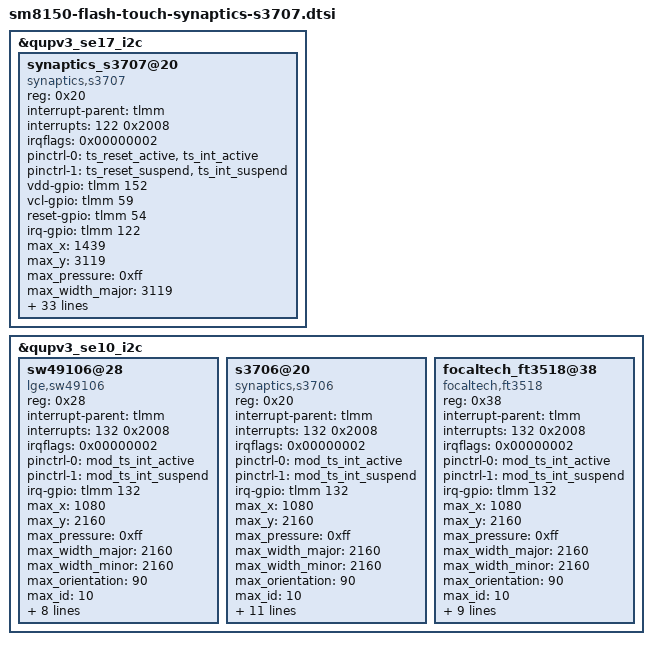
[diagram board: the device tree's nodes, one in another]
/* Copyright (c) 2014, The Linux Foundation. All rights reserved.
 *
 * This program is free software; you can redistribute it and/or modify
 * it under the terms of the GNU General Public License version 2 and
 * only version 2 as published by the Free Software Foundation.
 *
 * This program is distributed in the hope that it will be useful,
 * but WITHOUT ANY WARRANTY; without even the implied warranty of
 * MERCHANTABILITY or FITNESS FOR A PARTICULAR PURPOSE.  See the
 * GNU General Public License for more details.
 */


&qupv3_se17_i2c {
	status = "okay";

	synaptics_s3707@20 {
		status = "ok";
		compatible = "synaptics,s3707";

		reg = <0x20>;
		interrupt-parent = <&tlmm>;
		interrupts = <122 0x2008>;
		irqflags = <0x00000002>;

		pinctrl-names = "touch_pin_active", "touch_pin_sleep";
		pinctrl-0 = <&ts_reset_active &ts_int_active>;
		pinctrl-1 = <&ts_reset_suspend &ts_int_suspend>;

		vdd-gpio = <&tlmm 152 0x00>;
		vcl-gpio = <&tlmm 59 0x00>;
		reset-gpio = <&tlmm 54 0x00>;
		irq-gpio = <&tlmm 122 0x2008>;

		/* Caps */
		max_x = <1439>;
		max_y = <3119>;
		max_pressure = <0xff>;
		max_width_major = <3119>;
		max_width_minor = <3119>;
		max_orientation = <90>;
		max_id = <10>;
		hw_reset_delay = <100>;
		sw_reset_delay = <100>;

		/* Role */
		use_lpwg = <1>;
		use_lpwg_test = <1>;
		hide_coordinate = <1>;
		use_film_status = <1>;

		/* Firmware */
		fw_image = "touch/flash/main/lgd/PLG661-V1.08-PR2926255-s3707b_BLV86_DS5.10.81.1_50064188.img",
				"touch/flash/mfts/tianma/PLG670-V0.06-PR2910189-s3706b_BLV86_DS5.10.81.2_60062106.img",
				"touch/flash/mfts/tovis/PLG676-V0.06-PR2992791-s3707b_BLV86_DS5.10.81.2_20062106.img";
		panel_spec = "touch/flash/main/lgd/flash_limit.txt",
					"touch/flash/mfts/tianma/flash_tianma_limit.txt",
					"touch/flash/mfts/tovis/flash_tovis_limit.txt";
		panel_spec_mfts_folder = "touch/flash/main/lgd/flash_limit_mfts.txt",
					"touch/flash/mfts/tianma/flash_tianma_limit_mfts.txt",
					"touch/flash/mfts/tovis/flash_tovis_limit_mfts.txt";

		/* Performance Test */
		use_perf_test = <1>;
		test_delay = <8>;
		test_pressure = <50>;
		test_width = <100>;
		click_test_x = <180>;
		click_test_y = <756>;
		v_drag_test_x = <144>;
		v_drag_test_start_y = <1971>;
		v_drag_test_end_y = <1148>;
		h_drag_test_start_x = <1131>;
		h_drag_test_end_x = <308>;
		h_drag_test_y = <2184>;
	};
};

&qupv3_se10_i2c {
	status = "okay";

	sw49106@28 {
		compatible = "lge,sw49106";
		status = "ok";

		reg = <0x28>;
		interrupt-parent = <&tlmm>;
		interrupts = <132 0x2008>;
		irqflags = <0x00000002>;

		pinctrl-names = "module_touch_active","module_touch_sleep";	/*Touch GPIO pin name setting*/
		pinctrl-0 = <&mod_ts_int_active>;	/*Touch GPIO pin active setting*/
		pinctrl-1 = <&mod_ts_int_suspend>;	/*Touch GPIO pin suspend setting*/

//		vdd-gpio = <&tlmm 152 0x00>;
//		vcl-gpio = <&tlmm 59 0x00>;
//		reset-gpio = <&tlmm 54 0x00>;
		irq-gpio = <&tlmm 132 0x2008>;

		/* Caps */
		max_x = <1080>;
		max_y = <2160>;
		max_pressure = <0xff>;
		max_width_major = <2160>;
		max_width_minor = <2160>;
		max_orientation = <90>;
		max_id = <10>;
		hw_reset_delay = <210>;
		sw_reset_delay = <90>;

		fw_image = "touch/flash/module/temp/L0W55CV5_1_06.img";
		panel_spec = "touch/flash/module/temp/flash_limit.txt";
		panel_spec_mfts_folder = "touch/flash/module/temp/flash_limit_mfts.txt";
	};

	s3706@20 {
		compatible = "synaptics,s3706";
		status = "ok";

		reg = <0x20>;
		interrupt-parent = <&tlmm>;
		interrupts = <132 0x2008>;
		irqflags = <0x00000002>;

		pinctrl-names = "module_touch_active","module_touch_sleep";	/*Touch GPIO pin name setting*/
		pinctrl-0 = <&mod_ts_int_active>;	/*Touch GPIO pin active setting*/
		pinctrl-1 = <&mod_ts_int_suspend>;	/*Touch GPIO pin suspend setting*/

//		vdd-gpio = <&tlmm 152 0x00>;
//		vcl-gpio = <&tlmm 59 0x00>;
//		reset-gpio = <&tlmm 54 0x00>;
		irq-gpio = <&tlmm 132 0x2008>;

		/* Caps */
		max_x = <1080>;
		max_y = <2160>;
		max_pressure = <0xff>;
		max_width_major = <2160>;
		max_width_minor = <2160>;
		max_orientation = <90>;
		max_id = <10>;
		hw_reset_delay = <100>;
		sw_reset_delay = <100>;

		fw_image = "touch/flash/module/tianma/PLG670-V0.06-PR2910189-s3706b_BLV86_DS5.10.81.2_60062106.img",
				"touch/flash/module/tovis/PLG676-V0.06-PR2992791-s3707b_BLV86_DS5.10.81.2_20062106.img";
		panel_spec = "touch/flash/module/tianma/flash_module_tianma_limit.txt",
				"touch/flash/module/tovis/flash_module_tovis_limit.txt";
		panel_spec_mfts_folder = "touch/flash/module/tianma/flash_module_tianma_limit_mfts.txt",
						"touch/flash/module/tovis/flash_module_tovis_limit_mfts.txt";
	};

	focaltech_ft3518@38 {
		compatible = "focaltech,ft3518";
		status = "ok";

		reg = <0x38>;
		interrupt-parent = <&tlmm>;
		interrupts = <132 0x2008>;
		irqflags = <0x00000002>;

		pinctrl-names = "module_touch_active","module_touch_sleep";	/*Touch GPIO pin name setting*/
		pinctrl-0 = <&mod_ts_int_active>;	/*Touch GPIO pin active setting*/
		pinctrl-1 = <&mod_ts_int_suspend>;	/*Touch GPIO pin suspend setting*/

//		vdd-gpio = <&tlmm 152 0x00>;
//		vcl-gpio = <&tlmm 59 0x00>;
//		reset-gpio = <&tlmm 54 0x00>;
		irq-gpio = <&tlmm 132 0x2008>;

		/* Caps */
		max_x = <1080>;
		max_y = <2160>;
		max_pressure = <0xff>;
		max_width_major = <2160>;
		max_width_minor = <2160>;
		max_orientation = <90>;
		max_id = <10>;
		hw_reset_delay = <300>;
		sw_reset_delay = <100>;

		/* 1st firmware should be Pramboot firmware to upgrade another,
		   2nd firmware should be actual firmware that we want to be upgraded */
		fw_image = "touch/flash/module/temp/L0W55CV5_1_06.img",
			 "touch/flash/module/temp/L0W55CV5_1_06.img";
		panel_spec = "touch/flash/module/temp/flash_limit.txt";
		panel_spec_mfts_folder = "touch/flash/module/temp/flash_limit_mfts.txt";
	};



};
